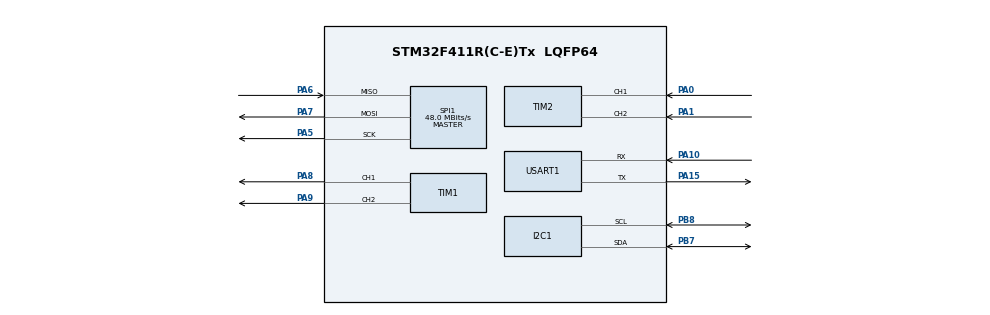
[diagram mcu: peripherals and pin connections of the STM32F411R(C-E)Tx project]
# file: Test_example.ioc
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FREERTOS.Tasks01=defaultTask,24,128,StartDefaultTask,Default,NULL,Dynamic,NULL,NULL
Mcu.Family=STM32F4
Mcu.Name=STM32F411R(C-E)Tx
Mcu.Package=LQFP64
NVIC.PriorityGroup=NVIC_PRIORITYGROUP_4
NVIC.TIM1_UP_TIM10_IRQn=true\:15\:0\:false\:false\:true\:false\:false\:true\:true
NVIC.TimeBase=TIM1_UP_TIM10_IRQn
NVIC.TimeBaseIP=TIM10
PA0-WKUP.Signal=S_TIM2_CH1_ETR
PA1.Signal=S_TIM2_CH2
PA10.Mode=Asynchronous
PA10.Signal=USART1_RX
PA13.Mode=Serial_Wire
PA13.Signal=SYS_JTMS-SWDIO
PA14.Mode=Serial_Wire
PA14.Signal=SYS_JTCK-SWCLK
PA15.Mode=Asynchronous
PA15.Signal=USART1_TX
PA5.Mode=Full_Duplex_Master
PA5.Signal=SPI1_SCK
PA6.Mode=Full_Duplex_Master
PA6.Signal=SPI1_MISO
PA7.Mode=Full_Duplex_Master
PA7.Signal=SPI1_MOSI
PA8.Signal=S_TIM1_CH1
PA9.Signal=S_TIM1_CH2
PB3.Signal=SYS_JTDO-SWO
PB7.Mode=I2C
PB7.Signal=I2C1_SDA
PB8.Mode=I2C
PB8.Signal=I2C1_SCL
PH0\ -\ OSC_IN.Mode=HSE-External-Oscillator
PH0\ -\ OSC_IN.Signal=RCC_OSC_IN
PH1\ -\ OSC_OUT.Mode=HSE-External-Oscillator
PH1\ -\ OSC_OUT.Signal=RCC_OSC_OUT
ProjectManager.HeapSize=0x200
ProjectManager.StackSize=0x400
ProjectManager.TargetToolchain=CMake
RCC.48MHZClocksFreq_Value=48000000
RCC.AHBFreq_Value=96000000
RCC.APB1CLKDivider=RCC_HCLK_DIV2
RCC.APB1Freq_Value=48000000
RCC.APB1TimFreq_Value=96000000
RCC.APB2Freq_Value=96000000
RCC.APB2TimFreq_Value=96000000
RCC.CortexFreq_Value=96000000
RCC.HCLKFreq_Value=96000000
RCC.HSE_VALUE=24000000
RCC.HSI_VALUE=16000000
RCC.LSE_VALUE=32768
RCC.PLLM=12
RCC.PLLN=96
RCC.PLLSourceVirtual=RCC_PLLSOURCE_HSE
RCC.SYSCLKFreq_VALUE=96000000
RCC.SYSCLKSource=RCC_SYSCLKSOURCE_PLLCLK
RCC.VCOOutputFreq_Value=192000000
SH.S_TIM1_CH1.0=TIM1_CH1,PWM Generation1 CH1
SH.S_TIM1_CH2.0=TIM1_CH2,PWM Generation2 CH2
SH.S_TIM2_CH1_ETR.0=TIM2_CH1,Encoder_Interface
SH.S_TIM2_CH2.0=TIM2_CH2,Encoder_Interface
SPI1.CalculateBaudRate=48.0 MBits/s
SPI1.Direction=SPI_DIRECTION_2LINES
SPI1.Mode=SPI_MODE_MASTER
SPI1.VirtualType=VM_MASTER
TIM1.Channel-PWM\ Generation1\ CH1=TIM_CHANNEL_1
TIM1.Channel-PWM\ Generation2\ CH2=TIM_CHANNEL_2
USART1.VirtualMode=VM_ASYNC
VP_FREERTOS_VS_CMSIS_V2.Mode=CMSIS_V2
VP_SYS_VS_tim10.Mode=TIM10
board=custom

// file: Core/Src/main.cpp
/* USER CODE BEGIN Header */
/**
  ******************************************************************************
  * @file           : main.c
  * @brief          : Main program body
  ******************************************************************************
  * @attention
  *
  * Copyright (c) 2026 STMicroelectronics.
  * All rights reserved.
  *
  * This software is licensed under terms that can be found in the LICENSE file
  * in the root directory of this software component.
  * If no LICENSE file comes with this software, it is provided AS-IS.
  *
  ******************************************************************************
  */
/* USER CODE END Header */
#include "main.h"
#include "gpio.h"
#include "i2c1.h"
#include "portmacro.h"
#include "spi1.h"
#include "tim1.h"
#include "tim2.h"
#include "usart1.h"
#include "FreeRTOS.h"
#include "task.h"
#include "queue.h"
#include "semphr.h"
#include <cstddef>

void StartDefaultTask(void *argument);

int main(void)
{
  HAL_Init();

  SystemClock_Config();

  MX_GPIO_Init();
  MX_I2C1_Init();
  MX_SPI1_Init();
  MX_TIM1_Init();
  MX_TIM2_Init();
  MX_USART1_UART_Init();

  /* this is the rtos task, we can create more to put into kernal*/
  BaseType_t result = xTaskCreate(
    StartDefaultTask,
    "defaultTask",
    512,
    NULL,
    2,
    NULL
  )

  if (result != pdPASS) {
    Error_Handler();
  }

  vTaskStartScheduler();

  /* Start scheduler */

  /* We should never get here as control is now taken by the scheduler */

  /* Infinite loop */
  /* USER CODE BEGIN WHILE */
  while (1)
  {

  }
}

void StartDefaultTask(void *argument)
{
  /* USER CODE BEGIN 5 */
  /* Infinite loop */
  while(1)
  {
    vTaskDelay(100);
  }
  /* USER CODE END 5 */
}

void HAL_TIM_PeriodElapsedCallback(TIM_HandleTypeDef *htim)
{
  if (htim->Instance == TIM10)
  {
    HAL_IncTick();
  }
}

void Error_Handler(void)
{
  __disable_irq();
  while (1)
  {
  }
}
